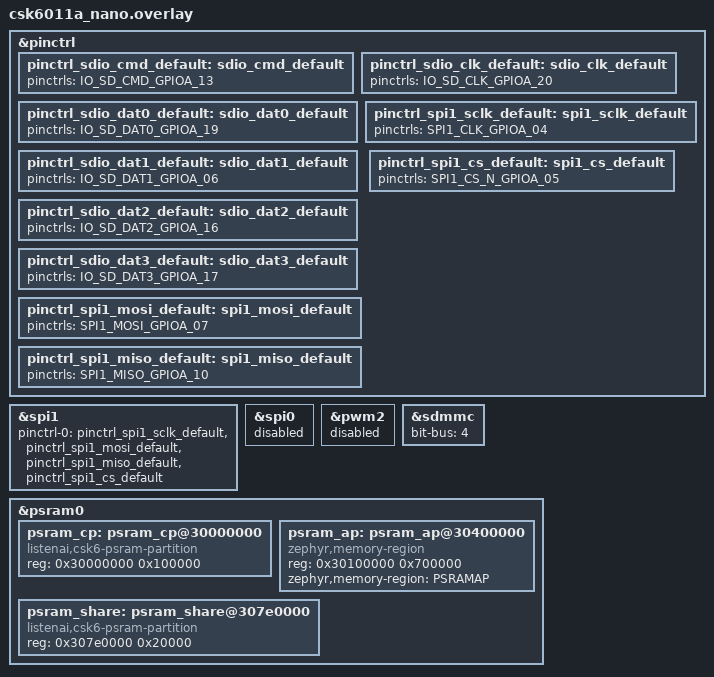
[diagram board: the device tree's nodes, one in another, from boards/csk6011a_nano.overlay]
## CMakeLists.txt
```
# SPDX-License-Identifier: Apache-2.0

cmake_minimum_required(VERSION 3.20.0)
find_package(Zephyr REQUIRED HINTS $ENV{ZEPHYR_BASE})
project(sdmmc)

target_sources(app PRIVATE src/main.c src/res_storage.c)
```

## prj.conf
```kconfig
CONFIG_DISK_ACCESS=y
CONFIG_DISK_DRIVER_SDMMC=y

CONFIG_LOG=y
CONFIG_LOG_MODE_MINIMAL=y

CONFIG_HEAP_MEM_POOL_SIZE=102400

CONFIG_TEST=y
CONFIG_ZTEST=y

# CONFIG_SHARED_MULTI_HEAP=y
CONFIG_DMA=y

CONFIG_CSK_HEAP=y
CONFIG_CSK_HEAP_MEM_POOL_SIZE=6291456

CONFIG_SPI=y
```

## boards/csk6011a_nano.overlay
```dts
/*
 * SPDX-License-Identifier: Apache-2.0
 */

/delete-node/ &psram_ap;
/delete-node/ &psram_cp;
/delete-node/ &psram_share;

&pinctrl{
    /* SDIO alternate function */
    pinctrl_sdio_cmd_default: sdio_cmd_default{
        pinctrls = <IO_SD_CMD_GPIOA_13>;
    };
    
    pinctrl_sdio_clk_default: sdio_clk_default{
        pinctrls = <IO_SD_CLK_GPIOA_20>;
    };

    pinctrl_sdio_dat0_default: sdio_dat0_default{
        pinctrls = <IO_SD_DAT0_GPIOA_19>;
    };

    pinctrl_sdio_dat1_default: sdio_dat1_default{
        pinctrls = <IO_SD_DAT1_GPIOA_06>;
    };

    pinctrl_sdio_dat2_default: sdio_dat2_default{
        pinctrls = <IO_SD_DAT2_GPIOA_16>;
    };

    pinctrl_sdio_dat3_default: sdio_dat3_default{
        pinctrls = <IO_SD_DAT3_GPIOA_17>;
    };

    /* SPIC alternate function */
    pinctrl_spi1_sclk_default: spi1_sclk_default{
            pinctrls = <SPI1_CLK_GPIOA_04>;
    };
    
    pinctrl_spi1_mosi_default: spi1_mosi_default{
            pinctrls = <SPI1_MOSI_GPIOA_07>;
    };

    pinctrl_spi1_miso_default: spi1_miso_default{
            pinctrls = <SPI1_MISO_GPIOA_10>;
    };    

    pinctrl_spi1_cs_default: spi1_cs_default{
            pinctrls = <SPI1_CS_N_GPIOA_05>;
    };
            
};

&spi1{
    pinctrl-0 = <&pinctrl_spi1_sclk_default &pinctrl_spi1_mosi_default &pinctrl_spi1_miso_default &pinctrl_spi1_cs_default>; 
    pinctrl-names = "default";
    status = "okay";
};

&spi0 {
    status = "disabled";
};

&pwm2 {
    status = "disabled";
};

&sdmmc {
    bit-bus = <4>;
};

&psram0 {
	psram_cp: psram_cp@30000000 {
		compatible = "listenai,csk6-psram-partition";
		reg = <0x30000000 0x100000>;
		status = "okay";
	};
	psram_ap: psram_ap@30400000 {
		compatible = "zephyr,memory-region","listenai,csk6-psram-partition";
		reg = <0x30100000 0x700000>;
		status = "okay";
		zephyr,memory-region = "PSRAMAP";
	};
	psram_share: psram_share@307e0000 {
		compatible = "listenai,csk6-psram-partition";
		reg = <0x307e0000 0x20000>;
		status = "okay";
	};
};
```

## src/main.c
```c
/*
 * SPDX-License-Identifier: Apache-2.0
 */

#include <zephyr/zephyr.h>
#include <ztest.h>
#include <zephyr/storage/disk_access.h>
#include <zephyr/device.h>
#include <logging/log.h>
#include <csk_malloc.h>
#include "res_storage.h"
LOG_MODULE_REGISTER(sample, LOG_LEVEL_DBG);

//使用限定sram内存下，测试读写不同长度的速率
uint32_t bytes_per_tests[4] = {1024 * 1024 * 2, 1024 * 1024 * 3, 1024 * 1024 * 4, 1024 * 1024 * 5};
uint32_t sram_size[2] = {1024 * 25, 1024 * 50};

void *psram_buf = NULL;

void test_csk_sdcard_setup(void)
{
	int rc;

	rc = res_storage_init();
	zassert_equal(rc, 0, "res storage initialization failed");
}

void test_csk_sdcard_wr(void)
{
	int ret = 0;

	for(uint8_t i = 0; i < sizeof(bytes_per_tests)/sizeof(bytes_per_tests[0]); i++){
		psram_buf = csk_malloc(bytes_per_tests[i]);
		if(!psram_buf){
			LOG_ERR(" psram malloc err(0x%x) \n", bytes_per_tests[i]);
		}
		for(uint8_t j = 0; j < sizeof(sram_size)/sizeof(sram_size[0]); j++){
			res_storage_cgf_t cfg;
			cfg.inner_ram_size = sram_size[j];
			ret = res_storage_config(&cfg);
			zassert_equal(ret, 0, "res_storage_config failed 0x%x", cfg.inner_ram_size);

			LOG_INF(" data size:%d MB  sram buf size:%d KB \n", bytes_per_tests[i] / (1024 * 1024), sram_size[j] / 1024);
			ret = res_storage_copy(0, psram_buf, bytes_per_tests[i]);
			zassert_equal(ret, 0, "disk_sdmmc_tests failed, %d", ret);

		}

		csk_free(psram_buf);
	}
}

extern void spi_mock(void);
void test_main(void)
{
	spi_mock();
	ztest_test_suite(csk_sdcard_test,
			 ztest_unit_test(test_csk_sdcard_setup),
			 ztest_unit_test(test_csk_sdcard_wr)
			 );
	ztest_run_test_suite(csk_sdcard_test);
}
```

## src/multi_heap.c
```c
#include <init.h>
#include <zephyr/zephyr.h>
#include <zephyr/multi_heap/shared_multi_heap.h>

typedef struct region_map {
	struct shared_multi_heap_region region;
	uintptr_t p_addr;
}region_map_t;

region_map_t sys_region_map[] =
{
	{										
		.region = {								
			.addr = (uintptr_t) DT_REG_ADDR(DT_NODELABEL(psram_ap_nocache)),		
			.size = DT_REG_SIZE(DT_NODELABEL(psram_ap_nocache)),			
			.attr = DT_ENUM_IDX_OR(DT_NODELABEL(psram_ap_nocache), zephyr_memory_region_mpu, SMH_REG_ATTR_NUM),	
		},									\
	},
};

static inline enum smh_reg_attr mpu_to_reg_attr(int mpu_attr)
{
	/*
	 * All the memory regions defined in the DT with the MPU property `RAM`
	 * can be accessed and memory can be retrieved from using the attribute
	 * `SMH_REG_ATTR_CACHEABLE`.
	 *
	 * All the memory regions defined in the DT with the MPU property
	 * `RAM_NOCACHE` can be accessed and memory can be retrieved from using
	 * the attribute `SMH_REG_ATTR_NON_CACHEABLE`.
	 *
	 * [MPU attr]   -> [SMH attr]
	 *
	 * RAM          -> SMH_REG_ATTR_CACHEABLE
	 * RAM_NOCACHE  -> SMH_REG_ATTR_NON_CACHEABLE
	 */
	switch (mpu_attr) {
	case 0: /* RAM */
		return SMH_REG_ATTR_CACHEABLE;
	case 1: /* RAM_NOCACHE */
		return SMH_REG_ATTR_NON_CACHEABLE;
	default:
		return SMH_REG_ATTR_NUM;/* How ? */
	
	}

	/* whatever */
	return 0;
}
static void fill_multi_heap(void)
{
	struct region_map *reg_map;

	for (size_t idx = 0; idx < sizeof(sys_region_map)/sizeof(sys_region_map[0]); idx++) {
		reg_map = &sys_region_map[idx];

		/* Convert MPU attributes to shared-multi-heap capabilities */
		reg_map->region.attr = mpu_to_reg_attr(reg_map->region.attr);

		/* Assume for now that phys == virt */
		reg_map->p_addr = reg_map->region.addr;

		shared_multi_heap_add(&reg_map->region, NULL);
	}
}

int app_multi_heap_init(const struct device *dev){
  shared_multi_heap_pool_init();
  fill_multi_heap();
  return 0;
}

SYS_INIT(app_multi_heap_init, POST_KERNEL, 0);
```

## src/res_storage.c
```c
#include <zephyr/zephyr.h>
#include <zephyr/device.h>
#include <zephyr/storage/disk_access.h>

#include "res_storage.h"

#include <logging/log.h>
LOG_MODULE_REGISTER(res_storage);

#define TRACE_TIME_COST (1)

typedef struct {
    const char *disk_pdrv;
    uint32_t disk_sector_count;
    uint32_t disk_sector_size;
    void *inner_buffer;
    uint32_t inner_ram_size;
} res_storage_info_t;

res_storage_info_t res_storage;

int res_storage_init(void)
{
    int rc = 0;
    uint32_t cmd_buf;

    res_storage.disk_pdrv = CONFIG_SDMMC_VOLUME_NAME;

	rc = disk_access_init(res_storage.disk_pdrv);
    if(rc != 0){
        LOG_ERR("Disk access initialization failed");
        return -1;
    }

	rc = disk_access_status(res_storage.disk_pdrv);
    if(rc != DISK_STATUS_OK){
        LOG_ERR("Disk status is not OK");
        return -1;
    }

	rc = disk_access_ioctl(res_storage.disk_pdrv, DISK_IOCTL_GET_SECTOR_COUNT, &cmd_buf);
    if(rc != 0){
        LOG_ERR("Disk ioctl get sector count failed");
        return -1;
    }

	LOG_INF("Disk reports %u sectors\n", cmd_buf);
	res_storage.disk_sector_count = cmd_buf;

	rc = disk_access_ioctl(res_storage.disk_pdrv, DISK_IOCTL_GET_SECTOR_SIZE, &cmd_buf);
    if(rc != 0){
        LOG_ERR("Disk ioctl get sector size faileds");
        return -1;
    }

	LOG_INF("Disk reports sector size %u\n", cmd_buf);
	res_storage.disk_sector_size = cmd_buf;

    return 0;
}

int res_storage_config(res_storage_cgf_t *cfg){

    if(res_storage.inner_buffer){
        k_free(res_storage.inner_buffer);
    }

    res_storage.inner_buffer = k_malloc(cfg->inner_ram_size);
    res_storage.inner_ram_size = cfg->inner_ram_size;
    if(!res_storage.inner_buffer){
        LOG_ERR("[%s %d] Failed to malloc", __FUNCTION__, __LINE__);
        return -1;
    }

    return 0;
}

int res_storage_copy(void *src, void *dst, uint32_t size){

    if(size % res_storage.disk_sector_size != 0 || size == 0){
        LOG_ERR("[%s %d] Failed to operation", __FUNCTION__, __LINE__);
        return -EIO;
    }

	int ret = 0;
	uint32_t read_time = 0;
	uint32_t num_sector = size/res_storage.disk_sector_size;
	uint32_t burst_num = res_storage.inner_ram_size/res_storage.disk_sector_size;

	read_time = k_uptime_get_32();
	for(uint32_t j = 0; j < num_sector; j+= burst_num){
		ret = disk_access_read(res_storage.disk_pdrv, res_storage.inner_buffer, j, burst_num);
		if (ret) {
			LOG_ERR("disk_access_write failed (%d)\n", ret);
			return -EIO;
		}
	}
	read_time = k_uptime_get_32() - read_time;

	LOG_INF(" read cost:%d(ms), rate:%3.1f MB/s  \n", read_time, (size * 1000.0)/(read_time * 1024 * 1024));

	return 0;
}
```

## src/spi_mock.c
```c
/*
 * SPDX-License-Identifier: Apache-2.0
 */

#include <kernel.h>
#include <string.h>
#include <errno.h>
#include <zephyr.h>
#include <sys/printk.h>
#include <device.h>
#include <drivers/spi.h>

#define TX_BUF_LEN	(4096)

// #define LOG_LEVEL 4
#include <logging/log.h>
LOG_MODULE_REGISTER(spi_mock);

K_THREAD_STACK_DEFINE(thread_stack, 2048);
struct k_thread spi_mock_thread;

const struct device *spi;

void spi_mock_thread_func(void *dummy1, void *dummy2, void *dummy3)
{
    (void)dummy1;
    (void)dummy2;
    (void)dummy3;

    struct spi_config spi_cfg = {0};
    /* spi master 8bit, LSB first*/
	spi_cfg.operation = SPI_WORD_SET(8) | SPI_OP_MODE_MASTER | SPI_TRANSFER_LSB;
	spi_cfg.frequency = 25 * 1000000UL;

    /* Make spi transaction package buffers */
	const int tx_package_num = 10;
	struct spi_buf *tx_package = k_calloc(tx_package_num, sizeof(struct spi_buf));
	if (tx_package == NULL) {
		LOG_ERR("tx_package calloc failed\n");
		return;
	}
	struct spi_buf_set tx_set;

	for (int tx_count = 0; tx_count < tx_package_num; tx_count++) {
		uint8_t *temp_buf = k_calloc(TX_BUF_LEN, sizeof(uint8_t));
		if (temp_buf == NULL) {
			LOG_ERR("temp_buf calloc failed\n");
			return;
		}

		tx_package[tx_count].len = TX_BUF_LEN;
		tx_package[tx_count].buf = temp_buf;
	}
	tx_set.buffers = tx_package;
	tx_set.count = tx_package_num;

	while (1) {
		LOG_INF("spi master sending data ...\n");
		spi_write(spi, &spi_cfg, &tx_set);
	}
}

void spi_mock(void)
{
	spi = DEVICE_DT_GET(DT_NODELABEL(spi1));
	if (!device_is_ready(spi)) {
		LOG_ERR("SPI device %s is not ready\n", spi->name);
		return;
	}

    k_thread_create(&spi_mock_thread, thread_stack,
                    K_THREAD_STACK_SIZEOF(thread_stack),
                    spi_mock_thread_func, NULL, NULL, NULL,
                    K_HIGHEST_APPLICATION_THREAD_PRIO, K_USER,
                    K_NO_WAIT);

}
```
